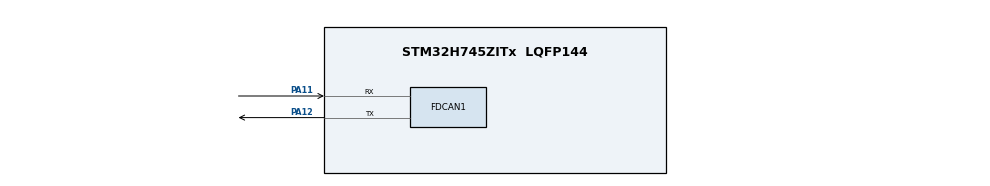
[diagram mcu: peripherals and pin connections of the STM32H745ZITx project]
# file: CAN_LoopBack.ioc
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CortexM4.IPs=BDMA,CORTEX_M4\:I,DEBUG,DMA,FATFS_M4\:I,FREERTOS_M4\:I,GPIO,IWDG2\:I,MDMA,NVIC2\:I,OPENAMP_M4\:I,PDM2PCM_M4\:I,PWR,RCC,RESMGR_UTILITY,SYS_M4\:I,USB_DEVICE_M4\:I,USB_HOST_M4\:I,VREFBUF,WWDG2\:I
CortexM7.IPs=BDMA\:I,CORTEX_M7\:I,DEBUG\:I,DMA\:I,FATFS_M7\:I,FREERTOS_M7\:I,GPIO\:I,IWDG1\:I,MDMA\:I,NVIC1\:I,OPENAMP_M7\:I,PDM2PCM_M7\:I,PWR\:I,RCC\:I,RESMGR_UTILITY\:I,SYS\:I,USB_DEVICE_M7\:I,USB_HOST_M7\:I,VREFBUF\:I,WWDG1\:I,FDCAN1\:I
FDCAN1.CalculateBaudRateNominal=500000
FDCAN1.CalculateTimeBitNominal=2000
FDCAN1.CalculateTimeQuantumNominal=20.0
FDCAN1.DataPrescaler=25
FDCAN1.DataTimeSeg1=2
FDCAN1.FrameFormat=FDCAN_FRAME_FD_NO_BRS
FDCAN1.Mode=FDCAN_MODE_INTERNAL_LOOPBACK
FDCAN1.NominalPrescaler=1
FDCAN1.NominalTimeSeg1=86
FDCAN1.NominalTimeSeg2=13
FDCAN1.RxFifo0ElmtsNbr=1
FDCAN1.StdFiltersNbr=1
FDCAN1.TxFifoQueueElmtsNbr=1
Mcu.Family=STM32H7
Mcu.Name=STM32H745ZITx
Mcu.Package=LQFP144
NVIC1.FDCAN1_IT0_IRQn=true\:0\:0\:false\:false\:true\:true\:true\:true
NVIC1.FDCAN1_IT1_IRQn=true\:0\:0\:false\:false\:true\:true\:true\:true
NVIC1.PriorityGroup=NVIC_PRIORITYGROUP_4
NVIC2.PriorityGroup=NVIC_PRIORITYGROUP_4
PA11.Mode=FDCAN_Activate
PA11.PinAttribute=CortexM7
PA11.Signal=FDCAN1_RX
PA12.Mode=FDCAN_Activate
PA12.PinAttribute=CortexM7
PA12.Signal=FDCAN1_TX
PC14-OSC32_IN\ (OSC32_IN).Mode=LSE-External-Oscillator
PC14-OSC32_IN\ (OSC32_IN).PinAttribute=CortexM7
PC14-OSC32_IN\ (OSC32_IN).Signal=RCC_OSC32_IN
PC15-OSC32_OUT\ (OSC32_OUT).Mode=LSE-External-Oscillator
PC15-OSC32_OUT\ (OSC32_OUT).PinAttribute=CortexM7
PC15-OSC32_OUT\ (OSC32_OUT).Signal=RCC_OSC32_OUT
PH0-OSC_IN\ (PH0).Mode=HSE-External-Oscillator
PH0-OSC_IN\ (PH0).PinAttribute=CortexM7
PH0-OSC_IN\ (PH0).Signal=RCC_OSC_IN
PH1-OSC_OUT\ (PH1).Mode=HSE-External-Oscillator
PH1-OSC_OUT\ (PH1).PinAttribute=CortexM7
PH1-OSC_OUT\ (PH1).Signal=RCC_OSC_OUT
ProjectManager.HeapSize=M4-0x200,M7-0x200
ProjectManager.StackSize=M4-0x400,M7-0x400
ProjectManager.TargetToolchain=STM32CubeIDE
RCC.ADCFreq_Value=50390625
RCC.APB1Freq_Value=100000000
RCC.APB2Freq_Value=100000000
RCC.APB3Freq_Value=100000000
RCC.APB4Freq_Value=100000000
RCC.CortexFreq_Value=200000000
RCC.DIVM1=2
RCC.DIVN1=32
RCC.DIVQ1=8
RCC.HCLKFreq_Value=100000000
RCC.HPRE=RCC_HCLK_DIV2
RCC.PLL2FRACN=0
RCC.PLL3FRACN=0
RCC.PLLFRACN=0
RCC.PLLSourceVirtual=RCC_PLLSOURCE_HSE
RCC.SYSCLKFreq_VALUE=200000000
RCC.SYSCLKSource=RCC_SYSCLKSOURCE_PLLCLK
RCC.USBFreq_Value=50000000
board=custom

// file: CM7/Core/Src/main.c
/* USER CODE BEGIN Header */
/**
 ******************************************************************************
 * @file           : main.c
 * @brief          : Main program body
 ******************************************************************************
 * @attention
 *
 * Copyright (c) 2023 STMicroelectronics.
 * All rights reserved.
 *
 * This software is licensed under terms that can be found in the LICENSE file
 * in the root directory of this software component.
 * If no LICENSE file comes with this software, it is provided AS-IS.
 *
 ******************************************************************************
 */
/* USER CODE END Header */
#include "main.h"

/* USER CODE BEGIN PD */

#ifndef HSEM_ID_0
#define HSEM_ID_0 (0U) /* HW semaphore 0*/
#endif

#define CAN_MessageID 0x100
/* USER CODE END PD */

FDCAN_HandleTypeDef hfdcan1;

/* USER CODE BEGIN PV */
FDCAN_FilterTypeDef CAN_IncomingDataFILTER ;
FDCAN_RxHeaderTypeDef CAN_IncomingDataHEADER ;
FDCAN_TxHeaderTypeDef CAN_SentDataHEADER ;

uint8_t CAN_SentData [8] = {'O', 0,0,0,0,0,0,0} ;
uint8_t CAN_RecievedData [8] = { 0 , 0 } ;
/* USER CODE END PV */

void SystemClock_Config(void);
static void MX_GPIO_Init(void);
static void MX_FDCAN1_Init(void);
/* USER CODE BEGIN PFP */

HAL_StatusTypeDef vCAN_FilterInit ( uint16_t ExpectedID ) ;
void vCAN_TX_HeaderInit ( void ) ;
void HAL_FDCAN_RxFifo0Callback(FDCAN_HandleTypeDef *hfdcan, uint32_t RxFifo0ITs);
/* USER CODE END PFP */

int main(void)
{
	/* USER CODE BEGIN Boot_Mode_Sequence_0 */
	int32_t timeout;
	/* USER CODE END Boot_Mode_Sequence_0 */

	/* USER CODE BEGIN Boot_Mode_Sequence_1 */
	/* USER CODE END Boot_Mode_Sequence_1 */
	/* MCU Configuration--------------------------------------------------------*/

	/* Reset of all peripherals, Initializes the Flash interface and the Systick. */
	HAL_Init();

	/* Configure the system clock */
	SystemClock_Config();
	/* USER CODE BEGIN Boot_Mode_Sequence_2 */
	/* USER CODE END Boot_Mode_Sequence_2 */

	/* Initialize all configured peripherals */
	MX_GPIO_Init();
	MX_FDCAN1_Init();
	/* USER CODE BEGIN 2 */
	vCAN_FilterInit( CAN_MessageID ) ;
	vCAN_TX_HeaderInit();
	HAL_FDCAN_Start(&hfdcan1) ;
	HAL_FDCAN_ActivateNotification(&hfdcan1, FDCAN_IT_RX_FIFO0_FULL , 0 ) ;
	HAL_Delay(100) ;
	HAL_FDCAN_AddMessageToTxFifoQ(&hfdcan1, &CAN_SentDataHEADER, CAN_SentData ) ;
	HAL_Delay(100) ;
	HAL_FDCAN_AddMessageToTxFifoQ(&hfdcan1, &CAN_SentDataHEADER, CAN_SentData ) ;

	/* USER CODE END 2 */

	/* Infinite loop */
	while (1)
	{

	}
}

void SystemClock_Config(void)
{
	RCC_OscInitTypeDef RCC_OscInitStruct = {0};
	RCC_ClkInitTypeDef RCC_ClkInitStruct = {0};

	/** Supply configuration update enable
	 */
	HAL_PWREx_ConfigSupply(PWR_DIRECT_SMPS_SUPPLY);

	/** Configure the main internal regulator output voltage
	 */
	__HAL_PWR_VOLTAGESCALING_CONFIG(PWR_REGULATOR_VOLTAGE_SCALE3);

	while(!__HAL_PWR_GET_FLAG(PWR_FLAG_VOSRDY)) {}

	/** Initializes the RCC Oscillators according to the specified parameters
	 * in the RCC_OscInitTypeDef structure.
	 */
	RCC_OscInitStruct.OscillatorType = RCC_OSCILLATORTYPE_HSE;
	RCC_OscInitStruct.HSEState = RCC_HSE_ON;
	RCC_OscInitStruct.PLL.PLLState = RCC_PLL_ON;
	RCC_OscInitStruct.PLL.PLLSource = RCC_PLLSOURCE_HSE;
	RCC_OscInitStruct.PLL.PLLM = 2;
	RCC_OscInitStruct.PLL.PLLN = 32;
	RCC_OscInitStruct.PLL.PLLP = 2;
	RCC_OscInitStruct.PLL.PLLQ = 8;
	RCC_OscInitStruct.PLL.PLLR = 2;
	RCC_OscInitStruct.PLL.PLLRGE = RCC_PLL1VCIRANGE_3;
	RCC_OscInitStruct.PLL.PLLVCOSEL = RCC_PLL1VCOWIDE;
	RCC_OscInitStruct.PLL.PLLFRACN = 0;
	if (HAL_RCC_OscConfig(&RCC_OscInitStruct) != HAL_OK)
	{
		Error_Handler();
	}

	/** Initializes the CPU, AHB and APB buses clocks
	 */
	RCC_ClkInitStruct.ClockType = RCC_CLOCKTYPE_HCLK|RCC_CLOCKTYPE_SYSCLK
			|RCC_CLOCKTYPE_PCLK1|RCC_CLOCKTYPE_PCLK2
			|RCC_CLOCKTYPE_D3PCLK1|RCC_CLOCKTYPE_D1PCLK1;
	RCC_ClkInitStruct.SYSCLKSource = RCC_SYSCLKSOURCE_PLLCLK;
	RCC_ClkInitStruct.SYSCLKDivider = RCC_SYSCLK_DIV1;
	RCC_ClkInitStruct.AHBCLKDivider = RCC_HCLK_DIV2;
	RCC_ClkInitStruct.APB3CLKDivider = RCC_APB3_DIV1;
	RCC_ClkInitStruct.APB1CLKDivider = RCC_APB1_DIV1;
	RCC_ClkInitStruct.APB2CLKDivider = RCC_APB2_DIV1;
	RCC_ClkInitStruct.APB4CLKDivider = RCC_APB4_DIV1;

	if (HAL_RCC_ClockConfig(&RCC_ClkInitStruct, FLASH_LATENCY_2) != HAL_OK)
	{
		Error_Handler();
	}
}

static void MX_FDCAN1_Init(void)
{

	hfdcan1.Instance = FDCAN1;
	hfdcan1.Init.FrameFormat = FDCAN_FRAME_FD_NO_BRS;
	hfdcan1.Init.Mode = FDCAN_MODE_INTERNAL_LOOPBACK;
	hfdcan1.Init.AutoRetransmission = DISABLE;
	hfdcan1.Init.TransmitPause = DISABLE;
	hfdcan1.Init.ProtocolException = DISABLE;
	hfdcan1.Init.NominalPrescaler = 1;
	hfdcan1.Init.NominalSyncJumpWidth = 1;
	hfdcan1.Init.NominalTimeSeg1 = 86;
	hfdcan1.Init.NominalTimeSeg2 = 13;
	hfdcan1.Init.DataPrescaler = 25;
	hfdcan1.Init.DataSyncJumpWidth = 1;
	hfdcan1.Init.DataTimeSeg1 = 2;
	hfdcan1.Init.DataTimeSeg2 = 1;
	hfdcan1.Init.MessageRAMOffset = 0;
	hfdcan1.Init.StdFiltersNbr = 1;
	hfdcan1.Init.ExtFiltersNbr = 0;
	hfdcan1.Init.RxFifo0ElmtsNbr = 2;
	hfdcan1.Init.RxFifo0ElmtSize = FDCAN_DATA_BYTES_8;
	hfdcan1.Init.RxFifo1ElmtsNbr = 0;
	hfdcan1.Init.RxFifo1ElmtSize = FDCAN_DATA_BYTES_8;
	hfdcan1.Init.RxBuffersNbr = 0;
	hfdcan1.Init.RxBufferSize = FDCAN_DATA_BYTES_8;
	hfdcan1.Init.TxEventsNbr = 0;
	hfdcan1.Init.TxBuffersNbr = 0;
	hfdcan1.Init.TxFifoQueueElmtsNbr = 1;
	hfdcan1.Init.TxFifoQueueMode = FDCAN_TX_FIFO_OPERATION;
	hfdcan1.Init.TxElmtSize = FDCAN_DATA_BYTES_8;
	if (HAL_FDCAN_Init(&hfdcan1) != HAL_OK)
	{
		Error_Handler();
	}

}

static void MX_GPIO_Init(void)
{

	/* GPIO Ports Clock Enable */
	__HAL_RCC_GPIOC_CLK_ENABLE();
	__HAL_RCC_GPIOH_CLK_ENABLE();
	__HAL_RCC_GPIOA_CLK_ENABLE();

}

/* USER CODE BEGIN 4 */

HAL_StatusTypeDef vCAN_FilterInit ( uint16_t ExpectedID )
{
	static uint16_t FilterCounter = 0 ;
	if ( FilterCounter > (hfdcan1.Init.StdFiltersNbr - 1) )
	{
		return (HAL_ERROR) ;
	}
	CAN_IncomingDataFILTER.FilterConfig = FDCAN_FILTER_TO_RXFIFO0 ;
	CAN_IncomingDataFILTER.FilterID1 	= ExpectedID << 5 ;
	CAN_IncomingDataFILTER.FilterID2 	= ExpectedID << 5 ;
	CAN_IncomingDataFILTER.FilterIndex 	= FilterCounter ;
	CAN_IncomingDataFILTER.FilterType 	= FDCAN_FILTER_MASK ;
	CAN_IncomingDataFILTER.IdType 		= FDCAN_STANDARD_ID ;
	FilterCounter ++ ;
	return ( HAL_FDCAN_ConfigFilter(&hfdcan1, &CAN_IncomingDataFILTER ) ) ;

}

void vCAN_TX_HeaderInit ( void )
{
	CAN_SentDataHEADER.BitRateSwitch = FDCAN_BRS_OFF ;
	CAN_SentDataHEADER.DataLength = FDCAN_DLC_BYTES_8 ;
	CAN_SentDataHEADER.FDFormat = FDCAN_CLASSIC_CAN ;
	CAN_SentDataHEADER.IdType = FDCAN_STANDARD_ID ;
	CAN_SentDataHEADER.Identifier = CAN_MessageID ;
	CAN_SentDataHEADER.MessageMarker = 0 ;
	CAN_SentDataHEADER.TxEventFifoControl = FDCAN_NO_TX_EVENTS ;
	CAN_SentDataHEADER.TxFrameType = FDCAN_DATA_FRAME ;

}

void HAL_FDCAN_RxFifo0Callback(FDCAN_HandleTypeDef *hfdcan, uint32_t RxFifo0ITs)
{

	HAL_FDCAN_GetRxMessage(&hfdcan1, FDCAN_RX_FIFO0 , &CAN_IncomingDataHEADER, CAN_RecievedData ) ;
	HAL_GPIO_TogglePin(GPIOE, GPIO_PIN_14 ) ;
}

/* USER CODE END 4 */

void Error_Handler(void)
{
	__disable_irq();
	while (1)
	{
	}
}
